# MCU_NAVSS0_UDMASS_INTA0_CFG register map
Vendor: Texas Instruments
Peripheral module from a debugger description file (folder J7VCL).
Registers are 64-bit, read-only, reset 0x66965100 unless marked. A register's access mark holds for its fields unless they carry their own. Offsets are as the file gives them; lines under a group give offsets from that group; [hi:lo] are bit positions; {n}, {i} and the like mark numbered series; 'fields as' and 'values as' point back to an identical list; <NAME> marks a mode.

## MCU_NAVSS0_UDMASS_INTA0_CFG
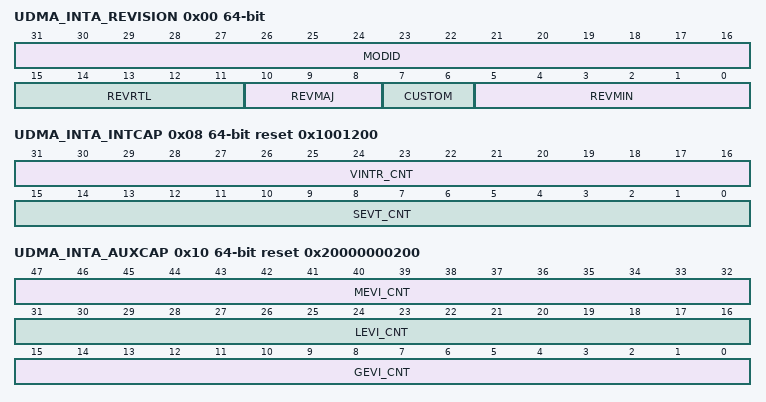
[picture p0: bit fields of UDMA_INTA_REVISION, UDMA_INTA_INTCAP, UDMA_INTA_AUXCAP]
0x00 UDMA_INTA_REVISION — The Revision Register contains the major and minor revisions for the module.
  [31:16] MODID — Module ID field
  [15:11] REVRTL — RTL revisioн
  [10:8] REVMAJ — Major revision
  [7:6] CUSTOM — Custom revision
  [5:0] REVMIN — Minor revision
0x08 UDMA_INTA_INTCAP reset 0x1001200 — The IntCap Register contains information on virtual interrupts.
  [31:16] VINTR_CNT — Virtual interrupt register/pin count
  [15:0] SEVT_CNT — Number of 'event to virt int' mapping registers. NOTE: This value is 600h for MCU_NAVSS0_UDMASS_INTR_AGGR0
0x10 UDMA_INTA_AUXCAP reset 0x20000000200 (reset mask 0xFFFF0000FFFF) — The AuxCap Register contains information on additional capabilities.
  [47:32] MEVI_CNT — Number of multicast event registers NOTE: This value is 100h for MCU_NAVSS0_UDMASS_INTR_AGGR0
  [31:16] LEVI_CNT — Local input events for local to global translation
  [15:0] GEVI_CNT — Number of event counting registers NOTE: This value is 80h for MCU_NAVSS0_UDMASS_INTR_AGGR0
